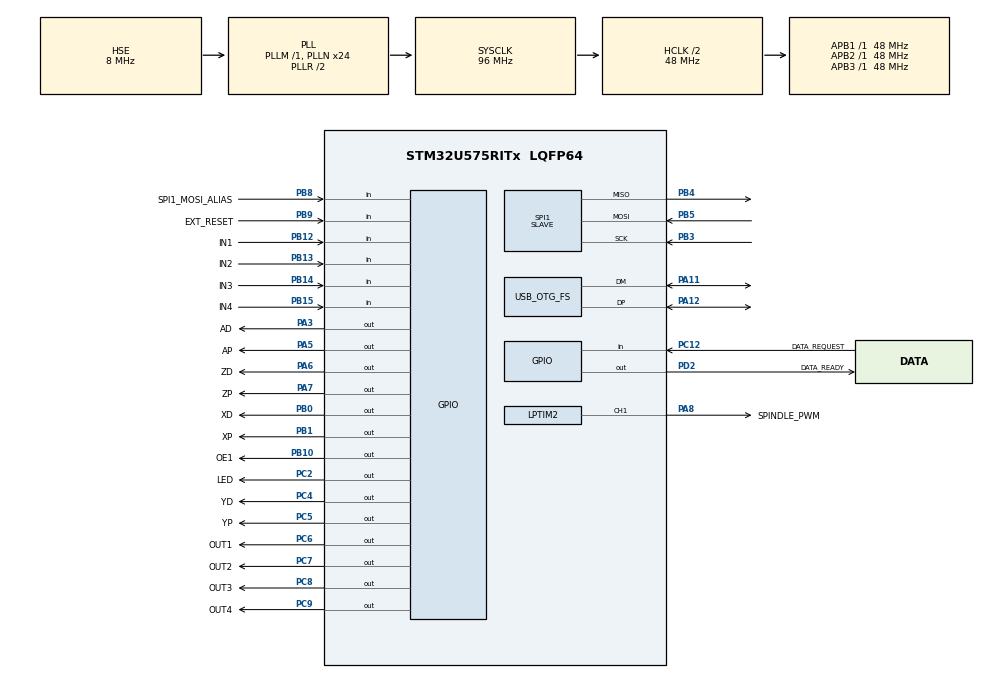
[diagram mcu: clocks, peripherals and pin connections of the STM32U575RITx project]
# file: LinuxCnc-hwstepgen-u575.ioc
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CORTEX_M33_NS.userName=CORTEX_M33
GPDMA1.CIRCULARMODE_GPDMACH10=ENABLE
GPDMA1.CIRCULARMODE_GPDMACH11=ENABLE
GPDMA1.DESTINC_GPDMACH11=DMA_DINC_INCREMENTED
GPDMA1.DIRECTION_GPDMACH10=DMA_MEMORY_TO_PERIPH
GPDMA1.IPHANDLE_GPDMACH10-SIMPLEREQUEST_GPDMACH10=__NULL
GPDMA1.IPHANDLE_GPDMACH11-SIMPLEREQUEST_GPDMACH11=__NULL
GPDMA1.REQUEST_GPDMACH10=GPDMA1_REQUEST_SPI1_TX
GPDMA1.REQUEST_GPDMACH11=GPDMA1_REQUEST_SPI1_RX
GPDMA1.SRCINC_GPDMACH10=DMA_SINC_INCREMENTED
GPDMA1.TRANSFERALLOCATEDPORTDEST_GPDMACH11=DMA_DEST_ALLOCATED_PORT0
Mcu.Family=STM32U5
Mcu.Name=STM32U575RITx
Mcu.Package=LQFP64
NVIC.GPDMA1_Channel10_IRQn=true\:0\:0\:false\:false\:true\:true\:true\:true
NVIC.GPDMA1_Channel11_IRQn=true\:0\:0\:false\:false\:true\:true\:true\:true
NVIC.OTG_FS_IRQn=true\:0\:0\:false\:false\:true\:true\:true\:true
NVIC.PriorityGroup=NVIC_PRIORITYGROUP_4
NVIC.SPI1_IRQn=true\:0\:0\:false\:false\:true\:false\:true\:true
NVIC.TIM7_IRQn=true\:0\:0\:false\:false\:true\:true\:true\:true
PA11.Mode=Device_Only
PA11.Signal=USB_OTG_FS_DM
PA12.Mode=Device_Only
PA12.Signal=USB_OTG_FS_DP
PA13\ (JTMS/SWDIO).Mode=Serial_Wire
PA13\ (JTMS/SWDIO).Signal=DEBUG_JTMS-SWDIO
PA14\ (JTCK/SWCLK).Mode=Serial_Wire
PA14\ (JTCK/SWCLK).Signal=DEBUG_JTCK-SWCLK
PA3.GPIO_Label=AD
PA3.Signal=GPIO_Output
PA5.GPIO_Label=AP
PA5.Signal=GPIO_Output
PA6.GPIO_Label=ZD
PA6.Signal=GPIO_Output
PA7.GPIO_Label=ZP
PA7.Signal=GPIO_Output
PA8.GPIO_Label=SPINDLE_PWM
PA8.Signal=S_LPTIM2_CH1
PB0.GPIO_Label=XD
PB0.Signal=GPIO_Output
PB1.GPIO_Label=XP
PB1.Signal=GPIO_Output
PB10.GPIO_Label=OE1
PB10.Signal=GPIO_Output
PB12.GPIO_Label=IN1
PB12.Signal=GPIO_Input
PB13.GPIO_Label=IN2
PB13.Signal=GPIO_Input
PB14.GPIO_Label=IN3
PB14.Signal=GPIO_Input
PB15.GPIO_Label=IN4
PB15.Signal=GPIO_Input
PB3\ (JTDO/TRACESWO).GPIO_Speed=GPIO_SPEED_FREQ_VERY_HIGH
PB3\ (JTDO/TRACESWO).Mode=Full_Duplex_Slave
PB3\ (JTDO/TRACESWO).Signal=SPI1_SCK
PB4\ (NJTRST).GPIO_Speed=GPIO_SPEED_FREQ_VERY_HIGH
PB4\ (NJTRST).Mode=Full_Duplex_Slave
PB4\ (NJTRST).Signal=SPI1_MISO
PB5.GPIO_Speed=GPIO_SPEED_FREQ_VERY_HIGH
PB5.Mode=Full_Duplex_Slave
PB5.Signal=SPI1_MOSI
PB8.GPIO_Label=SPI1_MOSI_ALIAS
PB8.Signal=GPIO_Input
PB9.GPIO_Label=EXT_RESET
PB9.Signal=GPIO_Input
PC12.GPIO_Label=DATA_REQUEST
PC12.Signal=GPIO_Input
PC2.GPIO_Label=LED
PC2.Signal=GPIO_Output
PC4.GPIO_Label=YD
PC4.Signal=GPIO_Output
PC5.GPIO_Label=YP
PC5.Signal=GPIO_Output
PC6.GPIO_Label=OUT1
PC6.Signal=GPIO_Output
PC7.GPIO_Label=OUT2
PC7.Signal=GPIO_Output
PC8.GPIO_Label=OUT3
PC8.Signal=GPIO_Output
PC9.GPIO_Label=OUT4
PC9.Signal=GPIO_Output
PD2.GPIO_Label=DATA_READY
PD2.Signal=GPIO_Output
PH0-OSC_IN\ (PH0).Mode=HSE-External-Oscillator
PH0-OSC_IN\ (PH0).Signal=RCC_OSC_IN
PH1-OSC_OUT\ (PH1).Mode=HSE-External-Oscillator
PH1-OSC_OUT\ (PH1).Signal=RCC_OSC_OUT
ProjectManager.HeapSize=0x400
ProjectManager.StackSize=0x800
ProjectManager.TargetToolchain=STM32CubeIDE
RCC.ADCFreq_Value=16000000
RCC.AHBCLKDivider=RCC_SYSCLK_DIV2
RCC.AHBFreq_Value=48000000
RCC.APB1Freq_Value=48000000
RCC.APB1TimFreq_Value=48000000
RCC.APB2Freq_Value=48000000
RCC.APB2TimFreq_Value=48000000
RCC.APB3Freq_Value=48000000
RCC.CortexFreq_Value=48000000
RCC.DACCLockSelectionVirtual=RCC_DAC1CLKSOURCE_LSI
RCC.EPOD_VALUE=8000000
RCC.HCLKFreq_Value=48000000
RCC.HSE_VALUE=8000000
RCC.HSI48_VALUE=48000000
RCC.HSI_VALUE=16000000
RCC.LSE_VALUE=32768
RCC.LSIDIV_VALUE=32000
RCC.MSI_VALUE=4000000
RCC.PLL2N=70
RCC.PLL3M=5
RCC.PLLFRACN=0
RCC.PLLN=24
RCC.PLLSourceVirtual=RCC_PLLSOURCE_HSE
RCC.SYSCLKFreq_VALUE=96000000
RCC.SYSCLKSource=RCC_SYSCLKSOURCE_PLLCLK
RCC.USBFreq_Value=48000000
RCC.VCOOutputFreq_Value=192000000
SH.S_LPTIM2_CH1.0=LPTIM2_CH1,OutputIO_CH1
SPI1.DataSize=SPI_DATASIZE_8BIT
SPI1.Direction=SPI_DIRECTION_2LINES
SPI1.Mode=SPI_MODE_SLAVE
SPI1.VirtualType=VM_SLAVE
TIM7.PeriodNoDither=499
USB_OTG_FS.VirtualMode=Device_Only
VP_DCACHE1_VS_DCACHE.Mode=DCACHE_Activate
VP_GPDMA1_VS_GPDMACH10.Mode=SIMPLEREQUEST_GPDMACH10
VP_GPDMA1_VS_GPDMACH11.Mode=SIMPLEREQUEST_GPDMACH11
VP_ICACHE_VS_ICACHE.Mode=DirectMappedCache
VP_LPBAMQUEUE_VS_QUEUE.Mode=QUEUEMODE
VP_LPBAM_VS_SIG1.Mode=SmartRun
VP_LPBAM_VS_SIG4.Mode=LPDMA1
VP_LPTIM2_VS_CH1.Mode=Channel_1_Active
VP_LPTIM2_VS_LPTIM_counterModeInternalClock.Mode=Counts__internal_clock_event_00
VP_PWR_VS_DBSignals.Mode=DisableDeadBatterySignals
VP_PWR_VS_LPOM.Mode=PowerOptimisation
VP_PWR_VS_SECSignals.Mode=Security/Privilege
VP_TIM7_VS_ClockSourceINT.Mode=Enable_Timer
board=custom

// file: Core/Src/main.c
/* USER CODE BEGIN Header */
/**
  ******************************************************************************
  * @file           : main.c
  * @brief          : Main program body
  ******************************************************************************
  * @attention
  *
  * Copyright (c) 2024 STMicroelectronics.
  * All rights reserved.
  *
  * This software is licensed under terms that can be found in the LICENSE file
  * in the root directory of this software component.
  * If no LICENSE file comes with this software, it is provided AS-IS.
  *
  ******************************************************************************
  */
/* USER CODE END Header */
#include "main.h"

/* USER CODE BEGIN Includes */
#include "usb_device.h"
/* USER CODE END Includes */

DCACHE_HandleTypeDef hdcache1;

LPTIM_HandleTypeDef hlptim2;

SPI_HandleTypeDef hspi1;
DMA_NodeTypeDef Node_GPDMA1_Channel11;
DMA_QListTypeDef List_GPDMA1_Channel11;
DMA_HandleTypeDef handle_GPDMA1_Channel11;
DMA_NodeTypeDef Node_GPDMA1_Channel10;
DMA_QListTypeDef List_GPDMA1_Channel10;
DMA_HandleTypeDef handle_GPDMA1_Channel10;

TIM_HandleTypeDef htim7;

PCD_HandleTypeDef hpcd_USB_OTG_FS;

void SystemClock_Config(void);
static void SystemPower_Config(void);
static void MX_GPIO_Init(void);
static void MX_GPDMA1_Init(void);
static void MX_ICACHE_Init(void);
static void MX_DCACHE1_Init(void);
static void MX_LPTIM2_Init(void);
static void MX_SPI1_Init(void);
static void MX_TIM7_Init(void);
static void MX_USB_OTG_FS_PCD_Init(void);

int main(void)
{

  /* MCU Configuration--------------------------------------------------------*/

  /* Reset of all peripherals, Initializes the Flash interface and the Systick. */
  HAL_Init();

  /* Configure the system clock */
  SystemClock_Config();

  /* Configure the System Power */
  SystemPower_Config();

  /* Initialize all configured peripherals */
  MX_GPIO_Init();
  MX_GPDMA1_Init();
  MX_ICACHE_Init();
  MX_DCACHE1_Init();
  MX_LPTIM2_Init();
  MX_SPI1_Init();
  MX_TIM7_Init();
  MX_USB_OTG_FS_PCD_Init();
  /* USER CODE BEGIN 2 */
  MX_USB_DEVICE_Init();
  //kernel_main_entry();
  /* USER CODE END 2 */

  /* Infinite loop */
  while (1)
  {

    //USBD_CUSTOM_HID_SendReport(&hUsbDeviceFS, data, sizeof(data));
  }
}

void SystemClock_Config(void)
{
  RCC_OscInitTypeDef RCC_OscInitStruct = {0};
  RCC_ClkInitTypeDef RCC_ClkInitStruct = {0};

  /** Configure the main internal regulator output voltage
  */
  if (HAL_PWREx_ControlVoltageScaling(PWR_REGULATOR_VOLTAGE_SCALE2) != HAL_OK)
  {
    Error_Handler();
  }

  /** Initializes the CPU, AHB and APB buses clocks
  */
  RCC_OscInitStruct.OscillatorType = RCC_OSCILLATORTYPE_HSI48|RCC_OSCILLATORTYPE_HSE;
  RCC_OscInitStruct.HSEState = RCC_HSE_ON;
  RCC_OscInitStruct.HSI48State = RCC_HSI48_ON;
  RCC_OscInitStruct.PLL.PLLState = RCC_PLL_ON;
  RCC_OscInitStruct.PLL.PLLSource = RCC_PLLSOURCE_HSE;
  RCC_OscInitStruct.PLL.PLLMBOOST = RCC_PLLMBOOST_DIV1;
  RCC_OscInitStruct.PLL.PLLM = 1;
  RCC_OscInitStruct.PLL.PLLN = 24;
  RCC_OscInitStruct.PLL.PLLP = 2;
  RCC_OscInitStruct.PLL.PLLQ = 2;
  RCC_OscInitStruct.PLL.PLLR = 2;
  RCC_OscInitStruct.PLL.PLLRGE = RCC_PLLVCIRANGE_1;
  RCC_OscInitStruct.PLL.PLLFRACN = 0;
  if (HAL_RCC_OscConfig(&RCC_OscInitStruct) != HAL_OK)
  {
    Error_Handler();
  }

  /** Initializes the CPU, AHB and APB buses clocks
  */
  RCC_ClkInitStruct.ClockType = RCC_CLOCKTYPE_HCLK|RCC_CLOCKTYPE_SYSCLK
                              |RCC_CLOCKTYPE_PCLK1|RCC_CLOCKTYPE_PCLK2
                              |RCC_CLOCKTYPE_PCLK3;
  RCC_ClkInitStruct.SYSCLKSource = RCC_SYSCLKSOURCE_PLLCLK;
  RCC_ClkInitStruct.AHBCLKDivider = RCC_SYSCLK_DIV2;
  RCC_ClkInitStruct.APB1CLKDivider = RCC_HCLK_DIV1;
  RCC_ClkInitStruct.APB2CLKDivider = RCC_HCLK_DIV1;
  RCC_ClkInitStruct.APB3CLKDivider = RCC_HCLK_DIV1;

  if (HAL_RCC_ClockConfig(&RCC_ClkInitStruct, FLASH_LATENCY_1) != HAL_OK)
  {
    Error_Handler();
  }
}

/**
  * @brief Power Configuration
  * @retval None
  */
static void SystemPower_Config(void)
{

  /*
   * Disable the internal Pull-Up in Dead Battery pins of UCPD peripheral
   */
  HAL_PWREx_DisableUCPDDeadBattery();
}

static void MX_DCACHE1_Init(void)
{

  hdcache1.Instance = DCACHE1;
  hdcache1.Init.ReadBurstType = DCACHE_READ_BURST_WRAP;
  if (HAL_DCACHE_Init(&hdcache1) != HAL_OK)
  {
    Error_Handler();
  }

}

static void MX_GPDMA1_Init(void)
{

  /* Peripheral clock enable */
  __HAL_RCC_GPDMA1_CLK_ENABLE();

  /* GPDMA1 interrupt Init */
    HAL_NVIC_SetPriority(GPDMA1_Channel10_IRQn, 0, 0);
    HAL_NVIC_EnableIRQ(GPDMA1_Channel10_IRQn);
    HAL_NVIC_SetPriority(GPDMA1_Channel11_IRQn, 0, 0);
    HAL_NVIC_EnableIRQ(GPDMA1_Channel11_IRQn);

}

static void MX_ICACHE_Init(void)
{

  /** Enable instruction cache in 1-way (direct mapped cache)
  */
  if (HAL_ICACHE_ConfigAssociativityMode(ICACHE_1WAY) != HAL_OK)
  {
    Error_Handler();
  }
  if (HAL_ICACHE_Enable() != HAL_OK)
  {
    Error_Handler();
  }

}

static void MX_LPTIM2_Init(void)
{

  LPTIM_OC_ConfigTypeDef sConfig1 = {0};

  hlptim2.Instance = LPTIM2;
  hlptim2.Init.Clock.Source = LPTIM_CLOCKSOURCE_APBCLOCK_LPOSC;
  hlptim2.Init.Clock.Prescaler = LPTIM_PRESCALER_DIV1;
  hlptim2.Init.Trigger.Source = LPTIM_TRIGSOURCE_SOFTWARE;
  hlptim2.Init.Period = 65535;
  hlptim2.Init.UpdateMode = LPTIM_UPDATE_IMMEDIATE;
  hlptim2.Init.CounterSource = LPTIM_COUNTERSOURCE_INTERNAL;
  hlptim2.Init.Input1Source = LPTIM_INPUT1SOURCE_GPIO;
  hlptim2.Init.Input2Source = LPTIM_INPUT2SOURCE_GPIO;
  hlptim2.Init.RepetitionCounter = 0;
  if (HAL_LPTIM_Init(&hlptim2) != HAL_OK)
  {
    Error_Handler();
  }
  sConfig1.Pulse = 0;
  sConfig1.OCPolarity = LPTIM_OCPOLARITY_HIGH;
  if (HAL_LPTIM_OC_ConfigChannel(&hlptim2, &sConfig1, LPTIM_CHANNEL_1) != HAL_OK)
  {
    Error_Handler();
  }
  HAL_LPTIM_MspPostInit(&hlptim2);

}

static void MX_SPI1_Init(void)
{

  SPI_AutonomousModeConfTypeDef HAL_SPI_AutonomousMode_Cfg_Struct = {0};

  /* SPI1 parameter configuration*/
  hspi1.Instance = SPI1;
  hspi1.Init.Mode = SPI_MODE_SLAVE;
  hspi1.Init.Direction = SPI_DIRECTION_2LINES;
  hspi1.Init.DataSize = SPI_DATASIZE_8BIT;
  hspi1.Init.CLKPolarity = SPI_POLARITY_LOW;
  hspi1.Init.CLKPhase = SPI_PHASE_1EDGE;
  hspi1.Init.NSS = SPI_NSS_SOFT;
  hspi1.Init.FirstBit = SPI_FIRSTBIT_MSB;
  hspi1.Init.TIMode = SPI_TIMODE_DISABLE;
  hspi1.Init.CRCCalculation = SPI_CRCCALCULATION_DISABLE;
  hspi1.Init.CRCPolynomial = 0x7;
  hspi1.Init.NSSPMode = SPI_NSS_PULSE_DISABLE;
  hspi1.Init.NSSPolarity = SPI_NSS_POLARITY_LOW;
  hspi1.Init.FifoThreshold = SPI_FIFO_THRESHOLD_01DATA;
  hspi1.Init.MasterSSIdleness = SPI_MASTER_SS_IDLENESS_00CYCLE;
  hspi1.Init.MasterInterDataIdleness = SPI_MASTER_INTERDATA_IDLENESS_00CYCLE;
  hspi1.Init.MasterReceiverAutoSusp = SPI_MASTER_RX_AUTOSUSP_DISABLE;
  hspi1.Init.MasterKeepIOState = SPI_MASTER_KEEP_IO_STATE_DISABLE;
  hspi1.Init.IOSwap = SPI_IO_SWAP_DISABLE;
  hspi1.Init.ReadyMasterManagement = SPI_RDY_MASTER_MANAGEMENT_INTERNALLY;
  hspi1.Init.ReadyPolarity = SPI_RDY_POLARITY_HIGH;
  if (HAL_SPI_Init(&hspi1) != HAL_OK)
  {
    Error_Handler();
  }
  HAL_SPI_AutonomousMode_Cfg_Struct.TriggerState = SPI_AUTO_MODE_DISABLE;
  HAL_SPI_AutonomousMode_Cfg_Struct.TriggerSelection = SPI_GRP1_GPDMA_CH0_TCF_TRG;
  HAL_SPI_AutonomousMode_Cfg_Struct.TriggerPolarity = SPI_TRIG_POLARITY_RISING;
  if (HAL_SPIEx_SetConfigAutonomousMode(&hspi1, &HAL_SPI_AutonomousMode_Cfg_Struct) != HAL_OK)
  {
    Error_Handler();
  }

}

static void MX_TIM7_Init(void)
{

  TIM_MasterConfigTypeDef sMasterConfig = {0};

  htim7.Instance = TIM7;
  htim7.Init.Prescaler = 0;
  htim7.Init.CounterMode = TIM_COUNTERMODE_UP;
  htim7.Init.Period = 499;
  htim7.Init.AutoReloadPreload = TIM_AUTORELOAD_PRELOAD_DISABLE;
  if (HAL_TIM_Base_Init(&htim7) != HAL_OK)
  {
    Error_Handler();
  }
  sMasterConfig.MasterOutputTrigger = TIM_TRGO_RESET;
  sMasterConfig.MasterSlaveMode = TIM_MASTERSLAVEMODE_DISABLE;
  if (HAL_TIMEx_MasterConfigSynchronization(&htim7, &sMasterConfig) != HAL_OK)
  {
    Error_Handler();
  }

}

static void MX_USB_OTG_FS_PCD_Init(void)
{

  hpcd_USB_OTG_FS.Instance = USB_OTG_FS;
  hpcd_USB_OTG_FS.Init.dev_endpoints = 6;
  hpcd_USB_OTG_FS.Init.phy_itface = PCD_PHY_EMBEDDED;
  hpcd_USB_OTG_FS.Init.Sof_enable = DISABLE;
  hpcd_USB_OTG_FS.Init.low_power_enable = DISABLE;
  hpcd_USB_OTG_FS.Init.lpm_enable = DISABLE;
  hpcd_USB_OTG_FS.Init.battery_charging_enable = DISABLE;
  hpcd_USB_OTG_FS.Init.use_dedicated_ep1 = DISABLE;
  hpcd_USB_OTG_FS.Init.vbus_sensing_enable = DISABLE;
  if (HAL_PCD_Init(&hpcd_USB_OTG_FS) != HAL_OK)
  {
    Error_Handler();
  }

}

static void MX_GPIO_Init(void)
{
  GPIO_InitTypeDef GPIO_InitStruct = {0};

  /* GPIO Ports Clock Enable */
  __HAL_RCC_GPIOH_CLK_ENABLE();
  __HAL_RCC_GPIOC_CLK_ENABLE();
  __HAL_RCC_GPIOA_CLK_ENABLE();
  __HAL_RCC_GPIOB_CLK_ENABLE();
  __HAL_RCC_GPIOD_CLK_ENABLE();

  /*Configure GPIO pin Output Level */
  HAL_GPIO_WritePin(GPIOC, LED_Pin|YD_Pin|YP_Pin|OUT1_Pin
                          |OUT2_Pin|OUT3_Pin|OUT4_Pin, GPIO_PIN_RESET);

  /*Configure GPIO pin Output Level */
  HAL_GPIO_WritePin(GPIOA, AD_Pin|AP_Pin|ZD_Pin|ZP_Pin, GPIO_PIN_RESET);

  /*Configure GPIO pin Output Level */
  HAL_GPIO_WritePin(GPIOB, XD_Pin|XP_Pin|OE1_Pin, GPIO_PIN_RESET);

  /*Configure GPIO pin Output Level */
  HAL_GPIO_WritePin(DATA_READY_GPIO_Port, DATA_READY_Pin, GPIO_PIN_RESET);

  /*Configure GPIO pins : LED_Pin YD_Pin YP_Pin OUT1_Pin
                           OUT2_Pin OUT3_Pin OUT4_Pin */
  GPIO_InitStruct.Pin = LED_Pin|YD_Pin|YP_Pin|OUT1_Pin
                          |OUT2_Pin|OUT3_Pin|OUT4_Pin;
  GPIO_InitStruct.Mode = GPIO_MODE_OUTPUT_PP;
  GPIO_InitStruct.Pull = GPIO_NOPULL;
  GPIO_InitStruct.Speed = GPIO_SPEED_FREQ_LOW;
  HAL_GPIO_Init(GPIOC, &GPIO_InitStruct);

  /*Configure GPIO pins : AD_Pin AP_Pin ZD_Pin ZP_Pin */
  GPIO_InitStruct.Pin = AD_Pin|AP_Pin|ZD_Pin|ZP_Pin;
  GPIO_InitStruct.Mode = GPIO_MODE_OUTPUT_PP;
  GPIO_InitStruct.Pull = GPIO_NOPULL;
  GPIO_InitStruct.Speed = GPIO_SPEED_FREQ_LOW;
  HAL_GPIO_Init(GPIOA, &GPIO_InitStruct);

  /*Configure GPIO pins : XD_Pin XP_Pin OE1_Pin */
  GPIO_InitStruct.Pin = XD_Pin|XP_Pin|OE1_Pin;
  GPIO_InitStruct.Mode = GPIO_MODE_OUTPUT_PP;
  GPIO_InitStruct.Pull = GPIO_NOPULL;
  GPIO_InitStruct.Speed = GPIO_SPEED_FREQ_LOW;
  HAL_GPIO_Init(GPIOB, &GPIO_InitStruct);

  /*Configure GPIO pins : IN1_Pin IN2_Pin IN3_Pin IN4_Pin
                           SPI1_MOSI_ALIAS_Pin EXT_RESET_Pin */
  GPIO_InitStruct.Pin = IN1_Pin|IN2_Pin|IN3_Pin|IN4_Pin
                          |SPI1_MOSI_ALIAS_Pin|EXT_RESET_Pin;
  GPIO_InitStruct.Mode = GPIO_MODE_INPUT;
  GPIO_InitStruct.Pull = GPIO_NOPULL;
  HAL_GPIO_Init(GPIOB, &GPIO_InitStruct);

  /*Configure GPIO pin : DATA_REQUEST_Pin */
  GPIO_InitStruct.Pin = DATA_REQUEST_Pin;
  GPIO_InitStruct.Mode = GPIO_MODE_INPUT;
  GPIO_InitStruct.Pull = GPIO_NOPULL;
  HAL_GPIO_Init(DATA_REQUEST_GPIO_Port, &GPIO_InitStruct);

  /*Configure GPIO pin : DATA_READY_Pin */
  GPIO_InitStruct.Pin = DATA_READY_Pin;
  GPIO_InitStruct.Mode = GPIO_MODE_OUTPUT_PP;
  GPIO_InitStruct.Pull = GPIO_NOPULL;
  GPIO_InitStruct.Speed = GPIO_SPEED_FREQ_LOW;
  HAL_GPIO_Init(DATA_READY_GPIO_Port, &GPIO_InitStruct);

}

void Error_Handler(void)
{
  __disable_irq();
  while (1)
  {
  }
}
